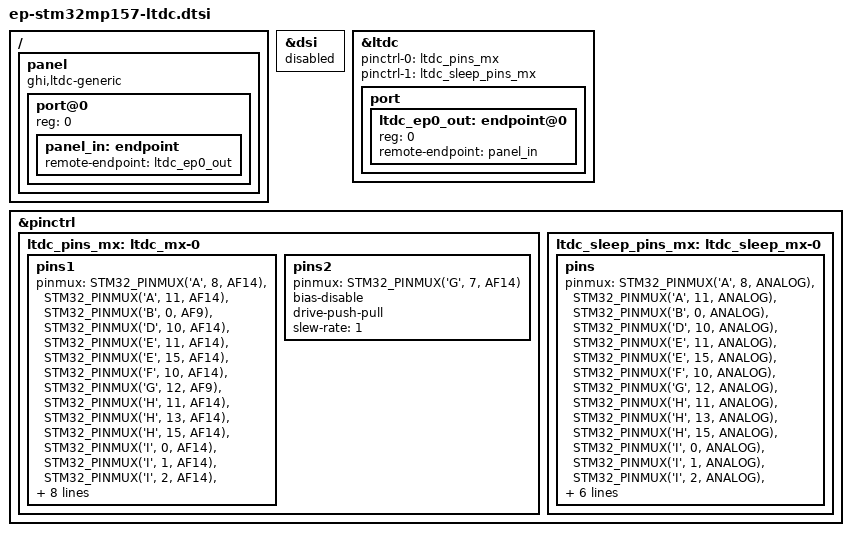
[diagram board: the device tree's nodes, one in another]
// SPDX-License-Identifier: (GPL-2.0+ OR BSD-3-Clause)
/*
 * Copyright (C) STMicroelectronics 2017 - All Rights Reserved
 * Author: Ludovic Barre <ludovic.barre@st.com> for STMicroelectronics.
 */
#include <dt-bindings/pinctrl/stm32-pinfunc.h>

/ {
	

	panel {
		compatible = "ghi,ltdc-generic", "panel-simple"; 		
		status = "okay";
		port@0 {
			reg = <0>;
			panel_in: endpoint {
				remote-endpoint = <&ltdc_ep0_out>;
			};
		};
	};	
};

&dsi {
	status = "disabled";	
};

&ltdc {
	pinctrl-names = "default", "sleep";
	pinctrl-0 = <&ltdc_pins_mx>;
	pinctrl-1 = <&ltdc_sleep_pins_mx>;
	status = "okay";
	
	port {
		ltdc_ep0_out: endpoint@0 {
			reg = <0>;
			remote-endpoint = <&panel_in>;
		};
	};
};

&pinctrl {
	ltdc_pins_mx: ltdc_mx-0 {
		pins1 {
			pinmux =  <STM32_PINMUX('A', 8, AF14)>, /* LTDC_R6 */
					  <STM32_PINMUX('A', 11, AF14)>, /* LTDC_R4 */
					<STM32_PINMUX('B', 0, AF9)>, /* LTDC_R3*/
					<STM32_PINMUX('D', 10, AF14)>, /* LTDC_B3*/
					<STM32_PINMUX('E', 11, AF14)>, /* LTDC_G3*/
					<STM32_PINMUX('E', 15, AF14)>, /* LTDC_R7*/
					<STM32_PINMUX('F', 10, AF14)>, /* LTDC_DE*/
					<STM32_PINMUX('G', 12, AF9)>, /* LTDC_B4*/
					<STM32_PINMUX('H', 11, AF14)>, /* LTDC_R5*/
					<STM32_PINMUX('H', 13, AF14)>, /* LTDC_G2*/
					<STM32_PINMUX('H', 15, AF14)>, /* LTDC_G4*/
					<STM32_PINMUX('I', 0, AF14)>, /* LTDC_G5*/
					<STM32_PINMUX('I', 1, AF14)>, /* LTDC_G6*/
					<STM32_PINMUX('I', 2, AF14)>, /* LTDC_G7*/
					<STM32_PINMUX('I', 5, AF14)>, /* LTDC_B5*/
					<STM32_PINMUX('I', 6, AF14)>, /* LTDC_B6*/
					<STM32_PINMUX('I', 7, AF14)>, /* LTDC_B7*/
					<STM32_PINMUX('I', 9, AF14)>, /* LTDC_VSYNC*/
					<STM32_PINMUX('I', 10, AF14)>; /* LTDC_HSYNC*/
					
			bias-disable;
			drive-push-pull;
			slew-rate = <0>;
		};
		pins2 {
			pinmux = <STM32_PINMUX('G', 7, AF14)>; /* LTDC_CLK*/
					
			
			bias-disable;
			drive-push-pull;
			slew-rate = <1>;
		};
	};

	ltdc_sleep_pins_mx: ltdc_sleep_mx-0 {
		pins {
			pinmux = <STM32_PINMUX('A', 8, ANALOG)>, /* LTDC_R6 */
					 <STM32_PINMUX('A', 11, ANALOG)>, /* LTDC_R4 */
					<STM32_PINMUX('B', 0, ANALOG)>, /* LTDC_R3*/
					<STM32_PINMUX('D', 10, ANALOG)>, /* LTDC_B3*/
					<STM32_PINMUX('E', 11, ANALOG)>, /* LTDC_G3*/
					<STM32_PINMUX('E', 15, ANALOG)>, /* LTDC_R7*/
					<STM32_PINMUX('F', 10, ANALOG)>, /* LTDC_DE*/
					<STM32_PINMUX('G', 12, ANALOG)>, /* LTDC_B4*/
					<STM32_PINMUX('H', 11, ANALOG)>, /* LTDC_R5*/
					<STM32_PINMUX('H', 13, ANALOG)>, /* LTDC_G2*/
					<STM32_PINMUX('H', 15, ANALOG)>, /* LTDC_G4*/
					<STM32_PINMUX('I', 0, ANALOG)>, /* LTDC_G5*/
					<STM32_PINMUX('I', 1, ANALOG)>, /* LTDC_G6*/
					<STM32_PINMUX('I', 2, ANALOG)>, /* LTDC_G7*/
					<STM32_PINMUX('I', 5, ANALOG)>, /* LTDC_B5*/
					<STM32_PINMUX('I', 6, ANALOG)>, /* LTDC_B6*/
					<STM32_PINMUX('I', 7, ANALOG)>, /* LTDC_B7*/
					<STM32_PINMUX('I', 9, ANALOG)>, /* LTDC_VSYNC*/
					<STM32_PINMUX('I', 10, ANALOG)>, /* LTDC_HSYNC*/
					<STM32_PINMUX('G', 7, ANALOG)>; /* LTDC_CLK*/
		};
	};

};
